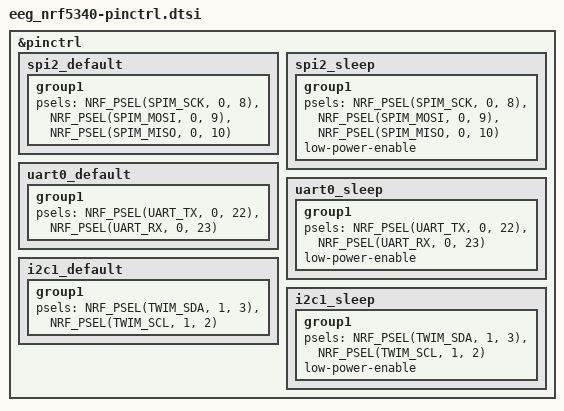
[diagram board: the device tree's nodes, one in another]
/*
 * Copyright (c) 2024
 * SPDX-License-Identifier: Apache-2.0
 */

&pinctrl {
	spi2_default: spi2_default {
		group1 {
			psels = <NRF_PSEL(SPIM_SCK, 0, 8)>,
				<NRF_PSEL(SPIM_MOSI, 0, 9)>,
				<NRF_PSEL(SPIM_MISO, 0, 10)>;
		};
	};

	spi2_sleep: spi2_sleep {
		group1 {
			psels = <NRF_PSEL(SPIM_SCK, 0, 8)>,
				<NRF_PSEL(SPIM_MOSI, 0, 9)>,
				<NRF_PSEL(SPIM_MISO, 0, 10)>;
			low-power-enable;
		};
	};

	uart0_default: uart0_default {
		group1 {
			psels = <NRF_PSEL(UART_TX, 0, 22)>,
				<NRF_PSEL(UART_RX, 0, 23)>;
		};
	};

	uart0_sleep: uart0_sleep {
		group1 {
			psels = <NRF_PSEL(UART_TX, 0, 22)>,
				<NRF_PSEL(UART_RX, 0, 23)>;
			low-power-enable;
		};
	};

	i2c1_default: i2c1_default {
		group1 {
			psels = <NRF_PSEL(TWIM_SDA, 1, 3)>,
				<NRF_PSEL(TWIM_SCL, 1, 2)>;
		};
	};

	i2c1_sleep: i2c1_sleep {
		group1 {
			psels = <NRF_PSEL(TWIM_SDA, 1, 3)>,
				<NRF_PSEL(TWIM_SCL, 1, 2)>;
			low-power-enable;
		};
	};
};
